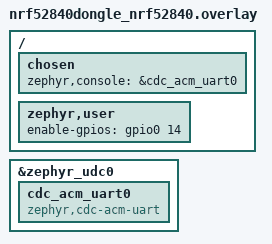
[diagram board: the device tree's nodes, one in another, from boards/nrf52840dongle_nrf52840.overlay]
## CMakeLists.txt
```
#
# Copyright (c) 2018 Nordic Semiconductor
#
# SPDX-License-Identifier: LicenseRef-Nordic-5-Clause
#
cmake_minimum_required(VERSION 3.20.0)

# Include project-level device tree additions (Power_on pin, io-channels, etc.)
#set(EXTRA_DTC_OVERLAY_FILE ${CMAKE_SOURCE_DIR}/ContinuousBiosensing.dts)

find_package(Zephyr REQUIRED HINTS $ENV{ZEPHYR_BASE})
project(NONE)

# NORDIC SDK APP START
target_sources(app PRIVATE
  src/main.c
  src/my_pbm.c
  src/hardware.c
  src/dac8831.c
)

# NORDIC SDK APP END
zephyr_library_include_directories(.)
```

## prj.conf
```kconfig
#
# Copyright (c) 2018 Nordic Semiconductor
#
# SPDX-License-Identifier: LicenseRef-Nordic-5-Clause
#

# Logger module
CONFIG_LOG=n #disabled logging for power efficiency
CONFIG_NCS_SAMPLES_DEFAULTS=n

#ENABLING CONFIG_ADC
CONFIG_ADC=y

# BLE Buffer and MTU Configuration - Increased for large data packets
CONFIG_BT_L2CAP_TX_BUF_COUNT=16
CONFIG_BT_ATT_PREPARE_COUNT=4
CONFIG_BT_CONN_TX_MAX=16
CONFIG_BT_L2CAP_TX_MTU=247
CONFIG_BT_BUF_ACL_RX_SIZE=251
CONFIG_BT_BUF_ACL_TX_SIZE=251

#RUNTIME REPORT 
CONFIG_THREAD_MONITOR=y
CONFIG_THREAD_RUNTIME_STATS=y
CONFIG_THREAD_ANALYZER=y
CONFIG_THREAD_NAME=y
CONFIG_THREAD_ANALYZER_AUTO=n
CONFIG_THREAD_ANALYZER_USE_PRINTK=y

# Button and LED library
CONFIG_DK_LIBRARY=y

# Bluetooth LE
CONFIG_BT=y
CONFIG_BT_PERIPHERAL=y
CONFIG_BT_DEVICE_NAME="PIBiomed_Nordic_CB_0"

# Increase stack size for the main thread and System Workqueue
CONFIG_SYSTEM_WORKQUEUE_STACK_SIZE=2048
CONFIG_MAIN_STACK_SIZE=2048

# BLE Stack Configuration - CRITICAL for callbacks
CONFIG_BT_RX_STACK_SIZE=4096
CONFIG_BT_HCI_TX_STACK_SIZE=1536

# Debug symbols for better reverse engineering
CONFIG_DEBUG=n
CONFIG_DEBUG_OPTIMIZATIONS=n
CONFIG_DEBUG_INFO=n # enable when activelt debugging 
#SPI Enable
CONFIG_SPI=y

# Internal flash storage for command_buffer persistence
CONFIG_FLASH=y
CONFIG_FLASH_MAP=y
CONFIG_FLASH_PAGE_LAYOUT=y
CONFIG_NVS=y

#Power optimization
CONFIG_SERIAL=n
CONFIG_CONSOLE=n
CONFIG_UART_CONSOLE=n

#Request Low Power Connection Parameters
CONFIG_BT_PERIPHERAL_PREF_MIN_INT=100
CONFIG_BT_PERIPHERAL_PREF_MAX_INT=120
CONFIG_BT_PERIPHERAL_PREF_TIMEOUT=200
CONFIG_BT_PERIPHERAL_PREF_LATENCY=2
```

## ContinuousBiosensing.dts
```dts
/*
 * ContinuousBiosensing project — custom device tree additions
 *
 * SPDX-License-Identifier: LicenseRef-Nordic-5-Clause
 */

/ {
	zephyr,user {
	};
};
```

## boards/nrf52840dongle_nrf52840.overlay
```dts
/*
 * Copyright (c) 2021 Nordic Semiconductor ASA
 *
 * SPDX-License-Identifier: LicenseRef-Nordic-5-Clause
 */

/ {
	chosen {
		zephyr,console = &cdc_acm_uart0;
	};

	zephyr,user {
		enable-gpios = <&gpio0 14 GPIO_ACTIVE_HIGH>;
	};
};

&zephyr_udc0 {
	cdc_acm_uart0: cdc_acm_uart0 {
		compatible = "zephyr,cdc-acm-uart";
	};
};
```

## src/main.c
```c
/*
 * Copyright (c) 2023 Nordic Semiconductor ASA
 *
 * SPDX-License-Identifier: LicenseRef-Nordic-5-Clause
 */

#include <zephyr/kernel.h>
#include <zephyr/logging/log.h>
#include <zephyr/bluetooth/bluetooth.h>
#include <zephyr/bluetooth/gap.h>
#include <zephyr/bluetooth/uuid.h>
#include <zephyr/bluetooth/conn.h>
#include <dk_buttons_and_leds.h>
#include <zephyr/drivers/gpio.h>
#include "my_pbm.h"
#include "my_pbm_service_table.h"
#include "hardware.h"



static const struct bt_le_adv_param *adv_param = BT_LE_ADV_PARAM(
	(BT_LE_ADV_OPT_CONNECTABLE |
	 BT_LE_ADV_OPT_USE_IDENTITY), /* Connectable advertising and use identity address */
	4800, /* Min Advertising Interval 500ms (800*0.625ms) */
	4808, /* Max Advertising Interval 500.625ms (801*0.625ms) */
	NULL); /* Set to NULL for undirected advertising */

LOG_MODULE_REGISTER(Lesson4_Exercise2, LOG_LEVEL_DBG);

#define DEVICE_NAME CONFIG_BT_DEVICE_NAME
#define DEVICE_NAME_LEN (sizeof(DEVICE_NAME) - 1)

#define RUN_STATUS_LED DK_LED1
#define CON_STATUS_LED DK_LED2
#define USER_LED DK_LED3
#define USER_BUTTON DK_BTN1_MSK

#define STACKSIZE 1024
#define PRIORITY 7

#define RUN_LED_BLINK_INTERVAL 1000
//#define NOTIFY_INTERVAL 500


void toggle_led2(void);
void toggle_led1(void);
void set_led2(bool state);
void set_led1(bool state);

static struct k_work adv_work;
static bool is_ble_connected = false;


static struct k_timer adv_led_timer;

static void adv_led_timer_handler(struct k_timer *timer_id)
{
    static bool on;
    if (!is_ble_connected) {
        on = !on;
        set_led1(on);
    }
}


static const struct bt_data ad[] = {
	BT_DATA_BYTES(BT_DATA_FLAGS, (BT_LE_AD_GENERAL | BT_LE_AD_NO_BREDR)),
	BT_DATA(BT_DATA_NAME_COMPLETE, DEVICE_NAME, DEVICE_NAME_LEN),
};

static const struct bt_data sd[] = {
	//BT_DATA_BYTES(BT_DATA_UUID128_ALL, BT_UUID_PBM_VAL),  // Main service only
	BT_DATA_BYTES(BT_DATA_UUID128_ALL, BT_UUID_PBM_ADVERTISING_VAL),  // Advertising service in scan response
};


static void adv_work_handler(struct k_work *work)
{
	int err = bt_le_adv_start(adv_param, ad, ARRAY_SIZE(ad), sd, ARRAY_SIZE(sd));

	if (err) {
		printk("Advertising failed to start (err %d)\n", err);
		return;
	}

	k_timer_start(&adv_led_timer, K_NO_WAIT, K_MSEC(RUN_LED_BLINK_INTERVAL));

	printk("Advertising successfully started\n");
}

static void advertising_start(void)
{
	k_work_submit(&adv_work);
}


static void on_connected(struct bt_conn *conn, uint8_t err)
{
	 if (err) {
        printk("Connection failed (err %u)\n", err);
        return;
    }

    printk("Connected\n");

	my_pbm_set_active_conn(conn);
	(void)my_pbm_request_slow_conn_params();
   

    is_ble_connected = true;
	k_timer_stop(&adv_led_timer);
    set_led1(false);
    set_led2(false);
}

static void on_disconnected(struct bt_conn *conn, uint8_t reason)
{
	printk("Disconnected (reason %u)\n", reason);

	is_ble_connected = false;
	set_led1(false);
	k_timer_start(&adv_led_timer, K_NO_WAIT, K_MSEC(RUN_LED_BLINK_INTERVAL));
	set_led2(false);
	my_pbm_clear_active_conn();
	/* Restart advertising after disconnection */
	advertising_start();
}

struct bt_conn_cb connection_callbacks = {
	.connected = on_connected,
	.disconnected = on_disconnected,
};



int main(void)
{
	//int blink_status = 0;
	int err;

	LOG_INF("Starting Lesson 4 - Exercise 2 \n");
	k_timer_init(&adv_led_timer, adv_led_timer_handler, NULL);


	err = bt_enable(NULL);
	if (err) {
		LOG_ERR("Bluetooth init failed (err %d)\n", err);
		return -1;
	}
	bt_conn_cb_register(&connection_callbacks);

	err = hw_init_all();
	if (err) {
		LOG_ERR("Hardware init failed (err %d)\n", err);
		return -1;
	}
	err = my_pbm_init();
	if (err) {
		printk("Failed to init LBS (err:%d)\n", err);
		return -1;
	}
	LOG_INF("Bluetooth initialized\n");
	k_work_init(&adv_work, adv_work_handler);
	advertising_start();
	
	// Main loop - blink system status LED and handle LED0 for advertising
	for (;;) {
		k_sleep(K_FOREVER);
	}
}
/* STEP 18.2 - Define and initialize a thread to send data periodically */
//K_THREAD_DEFINE(send_data_thread_id, STACKSIZE, send_data_thread, NULL, NULL, NULL, PRIORITY, 0, 0);
```

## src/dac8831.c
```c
/*
 * dac8831.c — Zephyr/NCS driver for the DAC8831 16-bit bipolar DAC
 *
 * SPI wiring:
 *   SCLK  → P0.07
 *   MOSI  → P0.05
 *   CS    → P0.08  (manually controlled via gpio0)
 *   MISO  → not connected (DAC is write-only)
 *
 * Board DTS requirement — add to your board DTS or overlay:
 *
 *   &spi0 {
 *       status = "okay";
 *       pinctrl-0 = <&spi0_default>;
 *       pinctrl-1 = <&spi0_sleep>;
 *       pinctrl-names = "default", "sleep";
 *   };
 *
 * And in pinctrl dtsi:
 *
 *   spi0_default: spi0_default {
 *       group1 {
 *           psels = <NRF_PSEL(SPIM_SCK,  0, 7)>,
 *                   <NRF_PSEL(SPIM_MOSI, 0, 5)>;
 *           nordic,drive-mode = <NRF_DRIVE_H0H1>;
 *       };
 *   };
 *   spi0_sleep: spi0_sleep {
 *       group1 {
 *           psels = <NRF_PSEL(SPIM_SCK,  0, 7)>,
 *                   <NRF_PSEL(SPIM_MOSI, 0, 5)>;
 *           low-power-enable;
 *       };
 *   };
 *
 * Usage example in my_pbm.c:
 *
 *   #include "dac8831.h"
 *
 *   // On startup:
 *   dac8831_init();                    // sets DAC output to 0V (0x8000)
 *
 *   // On CMD_START_CONTINUOUS event:
 *   dac8831_set_voltage(-400.0f);      // output -400 mV
 *
 *   // To output -500 mV:
 *   dac8831_set_voltage(-500.0f);
 */

#include "dac8831.h"

#include <zephyr/drivers/spi.h>
#include <zephyr/drivers/gpio.h>
#include <zephyr/logging/log.h>

LOG_MODULE_REGISTER(dac8831, LOG_LEVEL_INF);

/* ── Pin definitions ─────────────────────────────────────────────────────── */
#define DAC_CS_PIN    8U    /* P0.08 — chip select, active low */

/* ── DAC parameters ──────────────────────────────────────────────────────── */
#define DAC_VREF_V    1.8f          /* Reference voltage in volts            */
#define DAC_MIDCODE   0x8000U       /* Bipolar zero: (0 + 1.8) / 3.6 * 65536 */

/* ── Device handles ──────────────────────────────────────────────────────── */
static const struct device *spi_dev;   /* SPI0 controller                   */
static const struct device *cs_dev;    /* GPIO0 controller for manual CS    */

/*
 * SPI configuration:
 *   Mode 0: CPOL=0 (idle clock low), CPHA=0 (sample on rising edge)
 *   DAC8831 clocks SDI in on the rising edge of SCLK → Mode 0.
 *   MSB first, 8-bit words, 1 MHz, master mode, no hardware CS.
 */
static const struct spi_config dac_spi_cfg = {
    .frequency = MHZ(1),
    .operation = SPI_OP_MODE_MASTER |
                 SPI_WORD_SET(8)    |
                 SPI_TRANSFER_MSB,   /* CPOL=0, CPHA=0 = Mode 0 */
    .slave     = 0,
    .cs        = NULL,               /* CS managed manually below */
};

/* ── Internal: write a 16-bit code to the DAC ────────────────────────────── */
static void dac8831_write_code(uint16_t code)
{
    /* Split 16-bit code into two bytes, MSB first */
    uint8_t tx[2] = {
        (uint8_t)(code >> 8),    /* high byte */
        (uint8_t)(code & 0xFF),  /* low byte  */
    };

    struct spi_buf     tx_buf  = { .buf = tx, .len = sizeof(tx) };
    struct spi_buf_set tx_bufs = { .buffers = &tx_buf, .count = 1 };

    /* Assert CS low to begin transaction */
    gpio_pin_set(cs_dev, DAC_CS_PIN, 0);

    /* Send the two bytes over SPI */
    int ret = spi_write(spi_dev, &dac_spi_cfg, &tx_bufs);
    if (ret < 0) {
        LOG_ERR("SPI write failed: %d", ret);
    }

    /*
     * Deassert CS high.
     * LDAC is tied to GND, so the DAC register is transferred to the
     * output latch on this rising CS edge.
     */
    gpio_pin_set(cs_dev, DAC_CS_PIN, 1);
}

/* ── Public API ──────────────────────────────────────────────────────────── */

int dac8831_init(void)
{
    /* Obtain the SPI0 device handle from devicetree */
    spi_dev = DEVICE_DT_GET(DT_NODELABEL(spi0));
    if (!device_is_ready(spi_dev)) {
        LOG_ERR("SPI0 not ready — check board DTS pinctrl config");
        return -ENODEV;
    }

    /* Obtain the GPIO0 device handle for manual CS control */
    cs_dev = DEVICE_DT_GET(DT_NODELABEL(gpio0));
    if (!device_is_ready(cs_dev)) {
        LOG_ERR("GPIO0 not ready");
        return -ENODEV;
    }

    /* Configure CS pin as push-pull output, start deasserted (high) */
    int ret = gpio_pin_configure(cs_dev, DAC_CS_PIN, GPIO_OUTPUT_ACTIVE);
    if (ret < 0) {
        LOG_ERR("Failed to configure CS pin P0.%02u: %d", DAC_CS_PIN, ret);
        return ret;
    }

    /* Write midcode 0x8000 → 0V output in bipolar mode */
    dac8831_write_code(DAC_MIDCODE);
    LOG_INF("DAC8831 ready — output set to 0V (code 0x%04X)", DAC_MIDCODE);

    return 0;
}

void dac8831_set_voltage(float voltage_mv)
{
    /* Clamp input to the valid bipolar output range */
    if (voltage_mv >  1800.0f) {
        voltage_mv =  1800.0f;
    }
    if (voltage_mv < -1800.0f) {
        voltage_mv = -1800.0f;
    }

    /* Convert millivolts to volts */
    float vout = voltage_mv / 1000.0f;

    /*
     * Bipolar code formula (VREF = 1.8 V):
     *   Code = ((Vout + Vref) / (2 * Vref)) * 65536
     *
     * Examples:
     *   0 mV    → (1.8 / 3.6) * 65536 = 32768 = 0x8000
     *  -400 mV  → (1.4 / 3.6) * 65536 ≈ 25445 = 0x6365
     *  -500 mV  → (1.3 / 3.6) * 65536 ≈ 23662 = 0x5C6E
     */
    float code_f = ((vout + DAC_VREF_V) / (2.0f * DAC_VREF_V)) * 65536.0f;

    /* Guard against floating-point edge cases */
    if (code_f < 0.0f)     { code_f = 0.0f;     }
    if (code_f > 65535.0f) { code_f = 65535.0f; }

    uint16_t code = (uint16_t)code_f;

    LOG_INF("DAC8831: %.1f mV → code 0x%04X", (double)voltage_mv, code);
    dac8831_write_code(code);
}
```

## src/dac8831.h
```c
#ifndef DAC8831_H
#define DAC8831_H

#include <zephyr/kernel.h>

/**
 * @brief Initialize the DAC8831 SPI interface and output 0V.
 *
 * Configures SPI0 (Zephyr spi_write API), CPOL=0, CPHA=1 (Mode 1),
 * MSB first, 1 MHz. CS (P0.08) is managed manually via gpio0.
 * After init, writes 0x8000 to the DAC → 0V bipolar output (VREF=1.8V).
 *
 * Requires spi0 to be enabled in the board DTS with pinctrl:
 *   SCLK → P0.07, MOSI → P0.05, MISO → not connected.
 *
 * @retval 0        Success.
 * @retval -ENODEV  SPI or GPIO device not ready.
 * @retval Other    Zephyr error code.
 */
int dac8831_init(void);

/**
 * @brief Set the DAC8831 output voltage.
 *
 * Converts voltage_mv to a 16-bit bipolar code and sends it over SPI.
 *   Code = ((Vout_V + VREF) / (2 * VREF)) * 65536,  VREF = 1.8 V
 *
 * Input is clamped to [-1800 mV, +1800 mV]. LDAC is tied to GND so the
 * DAC output updates on the rising edge of CS.
 *
 * Examples:
 *   dac8831_set_voltage(   0.0f) → 0x8000 →  0.0 V
 *   dac8831_set_voltage(-400.0f) → 0x6C72 → -0.4 V
 *   dac8831_set_voltage(-500.0f) → 0x6893 → -0.5 V
 *
 * @param voltage_mv  Desired output in millivolts (-1800.0f to +1800.0f).
 */
void dac8831_set_voltage(float voltage_mv);

#endif /* DAC8831_H */
```

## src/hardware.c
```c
/*
 * Hardware Abstraction Layer
 * Handles all peripheral initialization and control: LEDs, GPIO, ADC
 */

#include "hardware.h"
#include <zephyr/drivers/gpio.h>
#include <zephyr/drivers/adc.h>
#include <zephyr/device.h>
#include <zephyr/logging/log.h>
#include <errno.h>

LOG_MODULE_REGISTER(hardware, LOG_LEVEL_INF);

// =============================================================================
// Device Tree Definitions
// =============================================================================

// LED GPIO specs from device tree aliases
#define LED1_NODE DT_ALIAS(led0)
#define LED2_NODE DT_ALIAS(led1)

static const struct gpio_dt_spec led1 = GPIO_DT_SPEC_GET(LED1_NODE, gpios);
static const struct gpio_dt_spec led2 = GPIO_DT_SPEC_GET(LED2_NODE, gpios);

// Measure pin from zephyr,user node (for oscilloscope timing verification)
#if DT_NODE_EXISTS(DT_PATH(zephyr_user)) && DT_NODE_HAS_PROP(DT_PATH(zephyr_user), measure_timing_gpios)
    #define MEASURE_PIN_NODE DT_PATH(zephyr_user)
    static const struct gpio_dt_spec measure_pin = 
        GPIO_DT_SPEC_GET(MEASURE_PIN_NODE, measure_timing_gpios);
    #define HAS_MEASURE_PIN 1
#else
    #define HAS_MEASURE_PIN 0
#endif

// =============================================================================
// ADC Configuration
// =============================================================================

// ADC channel specs from device tree zephyr,user node io-channels
#define ZEPHYR_USER_NODE DT_PATH(zephyr_user)

// ADC device
static const struct device *adc_dev = DEVICE_DT_GET(DT_IO_CHANNELS_CTLR(ZEPHYR_USER_NODE));

// ADC channels from io-channels property (physical channels 2 and 7)
static const uint8_t adc_channel_ids[] = {
    DT_IO_CHANNELS_INPUT_BY_IDX(ZEPHYR_USER_NODE, 0),  // First entry = channel 2
    DT_IO_CHANNELS_INPUT_BY_IDX(ZEPHYR_USER_NODE, 1),  // Second entry = channel 7
};

// ADC configuration structs initialized from device tree
static struct adc_channel_cfg adc_channel_cfgs[2];

static int16_t adc_sample_buffer;  // Buffer for ADC readings
static struct adc_sequence adc_sequence;

#define NUM_ADC_CHANNELS ARRAY_SIZE(adc_channel_ids)

static uint8_t active_adc_channel = 0;  // Currently active logical channel

// =============================================================================
// LED Functions
// =============================================================================

int led_init(void) {
    int ret;
    
    if (!gpio_is_ready_dt(&led1)) {
        LOG_ERR("LED1 device not ready");
        return -ENODEV;
    }
    
    if (!gpio_is_ready_dt(&led2)) {
        LOG_ERR("LED2 device not ready");
        return -ENODEV;
    }
    
    ret = gpio_pin_configure_dt(&led1, GPIO_OUTPUT_INACTIVE);
    if (ret < 0) {
        LOG_ERR("Failed to configure LED1: %d", ret);
        return ret;
    }
    
    ret = gpio_pin_configure_dt(&led2, GPIO_OUTPUT_INACTIVE);
    if (ret < 0) {
        LOG_ERR("Failed to configure LED2: %d", ret);
        return ret;
    }
    
    LOG_INF("LEDs initialized successfully");
    return 0;
}

void led1_on(void) {
    gpio_pin_set_dt(&led1, 1);
}

void led1_off(void) {
    gpio_pin_set_dt(&led1, 0);
}

void led1_set(bool state) {
    gpio_pin_set_dt(&led1, state ? 1 : 0);
}

void led1_toggle(void) {
    gpio_pin_toggle_dt(&led1);
}

void led2_on(void) {
    gpio_pin_set_dt(&led2, 1);
}

void led2_off(void) {
    gpio_pin_set_dt(&led2, 0);
}

void led2_set(bool state) {
    gpio_pin_set_dt(&led2, state ? 1 : 0);
}

void led2_toggle(void) {
    gpio_pin_toggle_dt(&led2);
}

// =============================================================================
// Measure Pin Functions
// =============================================================================

int measure_pin_init(void) {
#if HAS_MEASURE_PIN
    if (!gpio_is_ready_dt(&measure_pin)) {
        LOG_WRN("Measure pin device not ready");
        return -ENODEV;
    }
    
    int ret = gpio_pin_configure_dt(&measure_pin, GPIO_OUTPUT_INACTIVE);
    if (ret < 0) {
        LOG_ERR("Failed to configure measure pin: %d", ret);
        return ret;
    }
    
    LOG_INF("Measure pin initialized");
    return 0;
#else
    LOG_INF("Measure pin not configured in device tree, skipping");
    return 0;
#endif
}

void measure_pin_toggle(void) {
#if HAS_MEASURE_PIN
    gpio_pin_toggle_dt(&measure_pin);
#endif
}

void measure_pin_set(bool state) {
#if HAS_MEASURE_PIN
    gpio_pin_set_dt(&measure_pin, state ? 1 : 0);
#endif
}

// =============================================================================
// ADC Functions
// =============================================================================

int adc_init(void) {
    if (!device_is_ready(adc_dev)) {
        LOG_ERR("ADC device not ready");
        return -ENODEV;
    }
    
    // Initialize channel configs from device tree
    // Channel 0 (physical channel 2)
    adc_channel_cfgs[0].gain = ADC_GAIN_1_6;
    adc_channel_cfgs[0].reference = ADC_REF_INTERNAL;
    adc_channel_cfgs[0].acquisition_time = ADC_ACQ_TIME_DEFAULT;
    adc_channel_cfgs[0].channel_id = adc_channel_ids[0];
    
    // Channel 1 (physical channel 7)
    adc_channel_cfgs[1].gain = ADC_GAIN_1_6;
    adc_channel_cfgs[1].reference = ADC_REF_INTERNAL;
    adc_channel_cfgs[1].acquisition_time = ADC_ACQ_TIME_DEFAULT;
    adc_channel_cfgs[1].channel_id = adc_channel_ids[1];
    
    LOG_INF("ADC device initialized");
    return 0;
}

int adc_configure_channel(uint8_t channel) {
    // Validate logical channel number (0 or 1)
    if (channel >= NUM_ADC_CHANNELS) {
        LOG_ERR("Invalid logical channel %d (only 0-%d supported)", 
                channel, NUM_ADC_CHANNELS - 1);
        return -EINVAL;
    }
    
    // Check if ADC is ready
    if (!device_is_ready(adc_dev)) {
        LOG_ERR("ADC device not ready");
        return -ENODEV;
    }
    
    // Get the channel config
    struct adc_channel_cfg *cfg = &adc_channel_cfgs[channel];
    
    // Setup the channel
    int ret = adc_channel_setup(adc_dev, cfg);
    if (ret) {
        LOG_ERR("ADC channel %d setup failed with error %d", channel, ret);
        return ret;
    }
    
    // Initialize the ADC sequence for this channel
    adc_sequence.channels = BIT(cfg->channel_id);
    adc_sequence.buffer = &adc_sample_buffer;
    adc_sequence.buffer_size = sizeof(adc_sample_buffer);
    adc_sequence.resolution = 12;  // 12-bit resolution from DT
    
    active_adc_channel = channel;
    
    LOG_INF("ADC logical channel %d configured (physical channel %d)", 
            channel, cfg->channel_id);
    
    return 0;
}

uint16_t read_adc_single(void) {
    measure_pin_toggle();  // Toggle for oscilloscope timing
    
    int ret = adc_read(adc_dev, &adc_sequence);
    if (ret == 0) {
        return (uint16_t)adc_sample_buffer;  // Return raw value
    } else {
        LOG_ERR("ADC read failed with error %d", ret);
        return 0;
    }
}

uint16_t read_adc_averaged(uint8_t num_samples) {
    if (num_samples == 0) {
        LOG_WRN("Invalid num_samples (0), returning single read");
        return read_adc_single();
    }
    
    int32_t sum = 0;
    uint8_t successful_reads = 0;
    
    for (uint8_t i = 0; i < num_samples; i++) {
        int ret = adc_read(adc_dev, &adc_sequence);
        if (ret == 0) {
            sum += adc_sample_buffer;
            successful_reads++;
            LOG_DBG("Sample %d: %d, Running sum: %d", i, adc_sample_buffer, sum);
        } else {
            LOG_WRN("ADC read %d/%d failed", i + 1, num_samples);
        }
    }
    
    if (successful_reads == 0) {
        LOG_ERR("All ADC reads failed");
        return 0;
    }
    
    uint16_t average = (uint16_t)(sum / successful_reads);
    LOG_INF("ADC Sum: %d, Samples: %d, Average: %d", 
            sum, successful_reads, average);
    
    return average;
}

uint8_t adc_get_active_channel(void) {
    return active_adc_channel;
}

// =============================================================================
// Combined Initialization
// =============================================================================

int hw_init_all(void) {
    int ret;
    
    LOG_INF("=== Hardware Initialization Starting ===");
    
    // Initialize LEDs
    ret = led_init();
    if (ret < 0) {
        LOG_ERR("LED initialization failed: %d", ret);
        return ret;
    }
    
    // Initialize measure pin (optional)
    ret = measure_pin_init();
    if (ret < 0) {
        LOG_WRN("Measure pin init failed: %d (non-critical)", ret);
    }
    
    // Initialize ADC
    ret = adc_init();
    if (ret < 0) {
        LOG_ERR("ADC initialization failed: %d", ret);
        return ret;
    }
    
    // Configure default ADC channel (logical channel 0 = physical channel 2)
    ret = adc_configure_channel(0);
    if (ret < 0) {
        LOG_ERR("ADC channel 0 configuration failed: %d", ret);
        return ret;
    }
    
    LOG_INF("=== Hardware Initialization Complete ===");
    LOG_INF("Logical CH0 = Physical ADC channel %d", adc_channel_ids[0]);
    LOG_INF("Logical CH1 = Physical ADC channel %d", adc_channel_ids[1]);
    
    return 0;
}
```

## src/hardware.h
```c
#ifndef HARDWARE_H
#define HARDWARE_H

#include <stdint.h>
#include <stdbool.h>

// ============= Initialization =============
int hw_init_all(void);
int led_init(void);
int measure_pin_init(void);
int adc_init(void);

// ============= LED Control =============
void led1_on(void);
void led1_off(void);
void led1_set(bool state);
void led1_toggle(void);

void led2_on(void);
void led2_off(void);
void led2_set(bool state);
void led2_toggle(void);

// ============= Measure Pin (oscilloscope timing) =============
void measure_pin_toggle(void);
void measure_pin_set(bool state);

// ============= ADC Control =============
int adc_configure_channel(uint8_t channel);
uint16_t read_adc_single(void);
uint16_t read_adc_averaged(uint8_t num_samples);
uint8_t adc_get_active_channel(void);

#endif // HARDWARE_H
```

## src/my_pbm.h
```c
#ifndef MY_PBM_H
#define MY_PBM_H

#include <zephyr/types.h>
#include <zephyr/bluetooth/conn.h>


/** @brief Callback type for when an LED state change is received. */
typedef void (*led_cb_t)(const bool led_state);

/** @brief Callback type for when the button state is pulled. */
typedef bool (*button_cb_t)(void);

/** @brief Callback struct used by the PBM Service. */
struct my_pbm_cb {
	led_cb_t led_cb;
	button_cb_t button_cb;
};

typedef struct{
	int16_t e_ampl_pos;		    // config_buffer[2-3] // make it signed for debug 
	int16_t e_ampl_neg; 		// config_buffer[4-5]
	int16_t e_base;			    // config_buffer[6-7]
	int16_t e_end; 				// config_buffer[8-9]
	uint8_t pulse_freq; 		// config_buffer[10]
	uint8_t pw; 				// config_buffer[11]
	uint8_t delta_e; 			// config_buffer[12]
	uint8_t avg_num; 			// config_buffer[13]
	uint8_t sampling_rate; 		// config_buffer[14]
	uint16_t sampling_rate_hz;
	uint8_t EC_mode; 			// config_buffer[15]
} pbm_config_t;

extern volatile pbm_config_t g_cfg;


enum CommandType {
	CMD_STOP_ALL = 0x00,
    CMD_BATTERY_CHECK = 0x01,
    CMD_READ_CONFIG = 0x04,
    CMD_SET_CONFIG = 0x05,
	CMD_DEV_OFF = 0x07,
	CMD_START_SINGLE = 0x11,
    CMD_START_CONTINUOUS = 0x12,
	CMD_STOP_MEASUREMENT = 0x13,
};

extern uint8_t default_command[16];

int my_pbm_init(void);
int my_pbm_send_button_state_indicate(bool button_state);
int my_pbm_send_button_state_notify(bool button_state);
int my_pbm_send_sensor_notify(uint8_t *sensor_value);

void my_pbm_set_active_conn(struct bt_conn *conn);
void my_pbm_clear_active_conn(void);

int my_pbm_request_fast_conn_params(void);
int my_pbm_request_slow_conn_params(void);


#endif // MY_PBM_H
```
